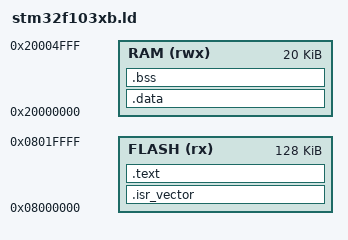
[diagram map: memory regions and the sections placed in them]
/* Linker script for STM32F103RB */
ENTRY(Reset_Handler)

MEMORY
{
    FLASH (rx) : ORIGIN = 0x08000000, LENGTH = 128K
    RAM (rwx) : ORIGIN = 0x20000000, LENGTH = 20K
}

_estack = ORIGIN(RAM) + LENGTH(RAM);

SECTIONS
{
    .isr_vector :
    {
        KEEP(*(.isr_vector))
    } > FLASH

    .text :
    {
        *(.text.Reset_Handler)
        *(.text*)
        *(.rodata*)
        KEEP(*(.init))
        KEEP(*(.fini))
    } > FLASH

    _etext = .;
    _sidata = _etext;

    .data : AT(_sidata)
    {
        _sdata = .;
        *(.data*)
        _edata = .;
    } > RAM

    .bss :
    {
        _sbss = .;
        *(.bss*)
        *(COMMON)
        _ebss = .;
    } > RAM

    . = ALIGN(4);
    _end = .;
}
